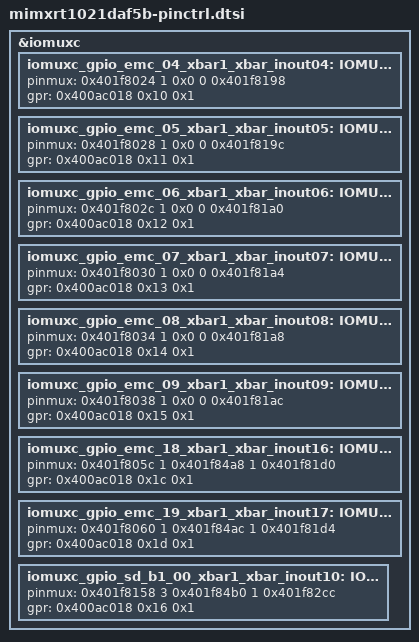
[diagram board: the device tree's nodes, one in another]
/*
 * Copyright 2024, NXP
 * SPDX-License-Identifier: Apache-2.0
 *
 * Note: File generated by gen_soc_headers.py
 * from configuration data for MIMXRT1021DAF5B
 */

/*
 * Delta-deduplicated by dedup_pinctrl.py:
 * based on mimxrt1024dag5a-pinctrl.dtsi with this part's differences applied
 * below (272 removed, 9 changed,
 * 0 added). Regenerate with dedup_pinctrl.py;
 * do not edit by hand.
 * target-hash: 459db1daa55398a1
 */

#include "mimxrt1024dag5a-pinctrl.dtsi"

/delete-node/ &iomuxc_gpio_ad_b0_13_arm_trace1;
/delete-node/ &iomuxc_gpio_ad_b0_14_arm_trace2;
/delete-node/ &iomuxc_gpio_ad_b0_15_arm_trace3;
/delete-node/ &iomuxc_gpio_ad_b1_06_acmp3_in3;
/delete-node/ &iomuxc_gpio_ad_b1_06_adc1_in6;
/delete-node/ &iomuxc_gpio_ad_b1_06_adc2_in6;
/delete-node/ &iomuxc_gpio_ad_b1_06_flexio1_flexio09;
/delete-node/ &iomuxc_gpio_ad_b1_06_flexpwm1_pwma0;
/delete-node/ &iomuxc_gpio_ad_b1_06_gpio1_io22;
/delete-node/ &iomuxc_gpio_ad_b1_06_kpp_col7;
/delete-node/ &iomuxc_gpio_ad_b1_06_lpspi1_pcs3;
/delete-node/ &iomuxc_gpio_ad_b1_06_lpuart2_cts_b;
/delete-node/ &iomuxc_gpio_ad_b1_06_sai1_rx_bclk;
/delete-node/ &iomuxc_gpio_ad_b1_06_usdhc1_reset_b;
/delete-node/ &iomuxc_gpio_ad_b1_07_acmp4_in3;
/delete-node/ &iomuxc_gpio_ad_b1_07_adc1_in7;
/delete-node/ &iomuxc_gpio_ad_b1_07_adc2_in7;
/delete-node/ &iomuxc_gpio_ad_b1_07_flexio1_flexio08;
/delete-node/ &iomuxc_gpio_ad_b1_07_flexpwm1_pwmb0;
/delete-node/ &iomuxc_gpio_ad_b1_07_gpio1_io23;
/delete-node/ &iomuxc_gpio_ad_b1_07_kpp_row7;
/delete-node/ &iomuxc_gpio_ad_b1_07_lpspi3_pcs3;
/delete-node/ &iomuxc_gpio_ad_b1_07_lpuart2_rts_b;
/delete-node/ &iomuxc_gpio_ad_b1_07_sai1_tx_data1;
/delete-node/ &iomuxc_gpio_ad_b1_07_usdhc1_vselect;
/delete-node/ &iomuxc_gpio_ad_b1_08_acmp1_in5;
/delete-node/ &iomuxc_gpio_ad_b1_08_adc1_in8;
/delete-node/ &iomuxc_gpio_ad_b1_08_adc2_in8;
/delete-node/ &iomuxc_gpio_ad_b1_08_flexio1_flexio07;
/delete-node/ &iomuxc_gpio_ad_b1_08_flexpwm1_pwma1;
/delete-node/ &iomuxc_gpio_ad_b1_08_gpio1_io24;
/delete-node/ &iomuxc_gpio_ad_b1_08_lpi2c2_scl;
/delete-node/ &iomuxc_gpio_ad_b1_08_lpspi3_pcs2;
/delete-node/ &iomuxc_gpio_ad_b1_08_lpuart2_tx;
/delete-node/ &iomuxc_gpio_ad_b1_08_sai1_tx_data2;
/delete-node/ &iomuxc_gpio_ad_b1_08_xbar1_xbar_in12;
/delete-node/ &iomuxc_gpio_ad_b1_08_xbar1_xbar_inout12;
/delete-node/ &iomuxc_gpio_ad_b1_09_acmp2_in5;
/delete-node/ &iomuxc_gpio_ad_b1_09_adc1_in9;
/delete-node/ &iomuxc_gpio_ad_b1_09_adc2_in9;
/delete-node/ &iomuxc_gpio_ad_b1_09_flexio1_flexio06;
/delete-node/ &iomuxc_gpio_ad_b1_09_flexpwm1_pwmb1;
/delete-node/ &iomuxc_gpio_ad_b1_09_gpio1_io25;
/delete-node/ &iomuxc_gpio_ad_b1_09_lpi2c2_sda;
/delete-node/ &iomuxc_gpio_ad_b1_09_lpspi3_pcs1;
/delete-node/ &iomuxc_gpio_ad_b1_09_lpuart2_rx;
/delete-node/ &iomuxc_gpio_ad_b1_09_sai1_tx_data3;
/delete-node/ &iomuxc_gpio_ad_b1_09_xbar1_xbar_in13;
/delete-node/ &iomuxc_gpio_ad_b1_09_xbar1_xbar_inout13;
/delete-node/ &iomuxc_gpio_emc_00_flexcan1_tx;
/delete-node/ &iomuxc_gpio_emc_00_gpio2_io00;
/delete-node/ &iomuxc_gpio_emc_00_lpspi2_sck;
/delete-node/ &iomuxc_gpio_emc_00_lpuart4_cts_b;
/delete-node/ &iomuxc_gpio_emc_00_pit_trigger2;
/delete-node/ &iomuxc_gpio_emc_00_qtimer2_timer0;
/delete-node/ &iomuxc_gpio_emc_00_semc_data00;
/delete-node/ &iomuxc_gpio_emc_00_spdif_sr_clk;
/delete-node/ &iomuxc_gpio_emc_01_flexcan1_rx;
/delete-node/ &iomuxc_gpio_emc_01_gpio2_io01;
/delete-node/ &iomuxc_gpio_emc_01_lpspi2_pcs0;
/delete-node/ &iomuxc_gpio_emc_01_lpuart4_rts_b;
/delete-node/ &iomuxc_gpio_emc_01_pit_trigger3;
/delete-node/ &iomuxc_gpio_emc_01_qtimer2_timer1;
/delete-node/ &iomuxc_gpio_emc_01_semc_data01;
/delete-node/ &iomuxc_gpio_emc_01_spdif_out;
/delete-node/ &iomuxc_gpio_emc_02_gpio2_io02;
/delete-node/ &iomuxc_gpio_emc_02_lpi2c1_scl;
/delete-node/ &iomuxc_gpio_emc_02_lpspi2_sdo;
/delete-node/ &iomuxc_gpio_emc_02_lpuart4_tx;
/delete-node/ &iomuxc_gpio_emc_02_qtimer2_timer2;
/delete-node/ &iomuxc_gpio_emc_02_semc_data02;
/delete-node/ &iomuxc_gpio_emc_02_spdif_lock;
/delete-node/ &iomuxc_gpio_emc_03_gpio2_io03;
/delete-node/ &iomuxc_gpio_emc_03_lpi2c1_sda;
/delete-node/ &iomuxc_gpio_emc_03_lpspi2_sdi;
/delete-node/ &iomuxc_gpio_emc_03_lpuart4_rx;
/delete-node/ &iomuxc_gpio_emc_03_qtimer2_timer3;
/delete-node/ &iomuxc_gpio_emc_03_semc_data03;
/delete-node/ &iomuxc_gpio_emc_03_spdif_ext_clk;
/delete-node/ &iomuxc_gpio_emc_10_flexpwm2_pwmx0;
/delete-node/ &iomuxc_gpio_emc_10_gpio2_io10;
/delete-node/ &iomuxc_gpio_emc_10_lpi2c4_sda;
/delete-node/ &iomuxc_gpio_emc_10_lpspi2_sck;
/delete-node/ &iomuxc_gpio_emc_10_sai1_tx_sync;
/delete-node/ &iomuxc_gpio_emc_10_semc_cas;
/delete-node/ &iomuxc_gpio_emc_10_xbar1_xbar_in10;
/delete-node/ &iomuxc_gpio_emc_10_xbar1_xbar_inout10;
/delete-node/ &iomuxc_gpio_emc_11_flexpwm2_pwmx1;
/delete-node/ &iomuxc_gpio_emc_11_gpio2_io11;
/delete-node/ &iomuxc_gpio_emc_11_lpi2c4_scl;
/delete-node/ &iomuxc_gpio_emc_11_lpspi2_pcs0;
/delete-node/ &iomuxc_gpio_emc_11_sai1_tx_bclk;
/delete-node/ &iomuxc_gpio_emc_11_semc_ras;
/delete-node/ &iomuxc_gpio_emc_11_xbar1_xbar_in11;
/delete-node/ &iomuxc_gpio_emc_11_xbar1_xbar_inout11;
/delete-node/ &iomuxc_gpio_emc_12_flexpwm2_pwmx2;
/delete-node/ &iomuxc_gpio_emc_12_gpio2_io12;
/delete-node/ &iomuxc_gpio_emc_12_lpspi2_sdo;
/delete-node/ &iomuxc_gpio_emc_12_lpuart6_tx;
/delete-node/ &iomuxc_gpio_emc_12_sai1_tx_data0;
/delete-node/ &iomuxc_gpio_emc_12_semc_cs0;
/delete-node/ &iomuxc_gpio_emc_12_xbar1_xbar_in12;
/delete-node/ &iomuxc_gpio_emc_12_xbar1_xbar_inout12;
/delete-node/ &iomuxc_gpio_emc_13_ccm_pmic_rdy;
/delete-node/ &iomuxc_gpio_emc_13_flexpwm2_pwmx3;
/delete-node/ &iomuxc_gpio_emc_13_gpio2_io13;
/delete-node/ &iomuxc_gpio_emc_13_lpspi2_sdi;
/delete-node/ &iomuxc_gpio_emc_13_lpuart6_rx;
/delete-node/ &iomuxc_gpio_emc_13_sai1_rx_data0;
/delete-node/ &iomuxc_gpio_emc_13_semc_ba0;
/delete-node/ &iomuxc_gpio_emc_13_xbar1_xbar_in13;
/delete-node/ &iomuxc_gpio_emc_13_xbar1_xbar_inout13;
/delete-node/ &iomuxc_gpio_emc_14_flexcan1_tx;
/delete-node/ &iomuxc_gpio_emc_14_gpio2_io14;
/delete-node/ &iomuxc_gpio_emc_14_lpspi2_pcs1;
/delete-node/ &iomuxc_gpio_emc_14_lpuart6_cts_b;
/delete-node/ &iomuxc_gpio_emc_14_sai1_rx_bclk;
/delete-node/ &iomuxc_gpio_emc_14_semc_ba1;
/delete-node/ &iomuxc_gpio_emc_14_xbar1_xbar_in14;
/delete-node/ &iomuxc_gpio_emc_14_xbar1_xbar_inout14;
/delete-node/ &iomuxc_gpio_emc_15_flexcan1_rx;
/delete-node/ &iomuxc_gpio_emc_15_gpio2_io15;
/delete-node/ &iomuxc_gpio_emc_15_lpuart6_rts_b;
/delete-node/ &iomuxc_gpio_emc_15_sai1_rx_sync;
/delete-node/ &iomuxc_gpio_emc_15_semc_addr10;
/delete-node/ &iomuxc_gpio_emc_15_wdog1_b;
/delete-node/ &iomuxc_gpio_emc_15_xbar1_xbar_in15;
/delete-node/ &iomuxc_gpio_emc_15_xbar1_xbar_inout15;
/delete-node/ &iomuxc_gpio_emc_28_ewm_out_b;
/delete-node/ &iomuxc_gpio_emc_28_flexpwm1_pwmx0;
/delete-node/ &iomuxc_gpio_emc_28_flexpwm2_pwma3;
/delete-node/ &iomuxc_gpio_emc_28_gpio2_io28;
/delete-node/ &iomuxc_gpio_emc_28_gpt2_capture2;
/delete-node/ &iomuxc_gpio_emc_28_sai3_mclk;
/delete-node/ &iomuxc_gpio_emc_28_semc_dqs;
/delete-node/ &iomuxc_gpio_emc_28_xbar1_xbar_in18;
/delete-node/ &iomuxc_gpio_emc_28_xbar1_xbar_inout18;
/delete-node/ &iomuxc_gpio_emc_29_flexpwm1_pwmx1;
/delete-node/ &iomuxc_gpio_emc_29_flexpwm2_pwmb3;
/delete-node/ &iomuxc_gpio_emc_29_gpio2_io29;
/delete-node/ &iomuxc_gpio_emc_29_gpt2_compare2;
/delete-node/ &iomuxc_gpio_emc_29_sai3_rx_bclk;
/delete-node/ &iomuxc_gpio_emc_29_semc_cke;
/delete-node/ &iomuxc_gpio_emc_29_wdog2_rst_b_deb;
/delete-node/ &iomuxc_gpio_emc_29_xbar1_xbar_in19;
/delete-node/ &iomuxc_gpio_emc_29_xbar1_xbar_inout19;
/delete-node/ &iomuxc_gpio_emc_30_flexpwm1_pwmx2;
/delete-node/ &iomuxc_gpio_emc_30_flexpwm2_pwma2;
/delete-node/ &iomuxc_gpio_emc_30_gpio2_io30;
/delete-node/ &iomuxc_gpio_emc_30_gpt2_compare3;
/delete-node/ &iomuxc_gpio_emc_30_lpuart4_cts_b;
/delete-node/ &iomuxc_gpio_emc_30_sai3_rx_sync;
/delete-node/ &iomuxc_gpio_emc_30_semc_clk;
/delete-node/ &iomuxc_gpio_emc_30_wdog1_rst_b_deb;
/delete-node/ &iomuxc_gpio_emc_31_flexpwm1_pwmx3;
/delete-node/ &iomuxc_gpio_emc_31_flexpwm2_pwmb2;
/delete-node/ &iomuxc_gpio_emc_31_gpio2_io31;
/delete-node/ &iomuxc_gpio_emc_31_gpt2_clk;
/delete-node/ &iomuxc_gpio_emc_31_lpuart4_rts_b;
/delete-node/ &iomuxc_gpio_emc_31_sai3_rx_data;
/delete-node/ &iomuxc_gpio_emc_31_semc_dm1;
/delete-node/ &iomuxc_gpio_emc_31_wdog2_b;
/delete-node/ &iomuxc_gpio_emc_36_ccm_pmic_rdy;
/delete-node/ &iomuxc_gpio_emc_36_enet_rx_clk;
/delete-node/ &iomuxc_gpio_emc_36_flexpwm2_pwma1;
/delete-node/ &iomuxc_gpio_emc_36_gpio3_io04;
/delete-node/ &iomuxc_gpio_emc_36_lpspi4_pcs1;
/delete-node/ &iomuxc_gpio_emc_36_lpuart5_cts_b;
/delete-node/ &iomuxc_gpio_emc_36_semc_data12;
/delete-node/ &iomuxc_gpio_emc_36_usdhc1_wp;
/delete-node/ &iomuxc_gpio_emc_37_enet_rx_data3;
/delete-node/ &iomuxc_gpio_emc_37_flexpwm2_pwmb1;
/delete-node/ &iomuxc_gpio_emc_37_gpio3_io05;
/delete-node/ &iomuxc_gpio_emc_37_lpspi4_pcs2;
/delete-node/ &iomuxc_gpio_emc_37_lpuart5_rts_b;
/delete-node/ &iomuxc_gpio_emc_37_mqs_right;
/delete-node/ &iomuxc_gpio_emc_37_semc_data13;
/delete-node/ &iomuxc_gpio_emc_37_usdhc1_vselect;
/delete-node/ &iomuxc_gpio_emc_38_enet_rx_data2;
/delete-node/ &iomuxc_gpio_emc_38_flexpwm2_pwma0;
/delete-node/ &iomuxc_gpio_emc_38_gpio3_io06;
/delete-node/ &iomuxc_gpio_emc_38_lpspi4_pcs3;
/delete-node/ &iomuxc_gpio_emc_38_lpuart5_tx;
/delete-node/ &iomuxc_gpio_emc_38_mqs_left;
/delete-node/ &iomuxc_gpio_emc_38_semc_data14;
/delete-node/ &iomuxc_gpio_emc_38_usdhc1_cd_b;
/delete-node/ &iomuxc_gpio_emc_39_enet_tx_er;
/delete-node/ &iomuxc_gpio_emc_39_flexpwm2_pwmb0;
/delete-node/ &iomuxc_gpio_emc_39_gpio3_io07;
/delete-node/ &iomuxc_gpio_emc_39_gpt1_clk;
/delete-node/ &iomuxc_gpio_emc_39_lpuart5_rx;
/delete-node/ &iomuxc_gpio_emc_39_semc_data15;
/delete-node/ &iomuxc_gpio_emc_39_usb_otg1_oc;
/delete-node/ &iomuxc_gpio_emc_39_wdog1_b;
/delete-node/ &iomuxc_gpio_emc_40_enet_mdio;
/delete-node/ &iomuxc_gpio_emc_40_enet_tx_data3;
/delete-node/ &iomuxc_gpio_emc_40_gpio3_io08;
/delete-node/ &iomuxc_gpio_emc_40_gpt1_compare3;
/delete-node/ &iomuxc_gpio_emc_40_semc_csx0;
/delete-node/ &iomuxc_gpio_emc_40_spdif_out;
/delete-node/ &iomuxc_gpio_emc_40_usb_otg1_id;
/delete-node/ &iomuxc_gpio_emc_40_xbar1_xbar_in18;
/delete-node/ &iomuxc_gpio_emc_40_xbar1_xbar_inout18;
/delete-node/ &iomuxc_gpio_emc_41_enet_mdc;
/delete-node/ &iomuxc_gpio_emc_41_enet_tx_data2;
/delete-node/ &iomuxc_gpio_emc_41_gpio3_io09;
/delete-node/ &iomuxc_gpio_emc_41_gpt1_compare2;
/delete-node/ &iomuxc_gpio_emc_41_semc_rdy;
/delete-node/ &iomuxc_gpio_emc_41_spdif_in;
/delete-node/ &iomuxc_gpio_emc_41_usb_otg1_pwr;
/delete-node/ &iomuxc_gpio_emc_41_xbar1_xbar_in19;
/delete-node/ &iomuxc_gpio_emc_41_xbar1_xbar_inout19;
/delete-node/ &iomuxc_gpio_sd_b0_00_flexspi_a_ss1_b;
/delete-node/ &iomuxc_gpio_sd_b0_00_gpio3_io13;
/delete-node/ &iomuxc_gpio_sd_b0_00_lpi2c3_scl;
/delete-node/ &iomuxc_gpio_sd_b0_00_qtimer1_timer0;
/delete-node/ &iomuxc_gpio_sd_b0_00_sai1_mclk;
/delete-node/ &iomuxc_gpio_sd_b0_00_sai2_mclk;
/delete-node/ &iomuxc_gpio_sd_b0_00_usdhc1_data2;
/delete-node/ &iomuxc_gpio_sd_b0_00_xbar1_xbar_in14;
/delete-node/ &iomuxc_gpio_sd_b0_00_xbar1_xbar_inout14;
/delete-node/ &iomuxc_gpio_sd_b0_01_flexspi_b_ss1_b;
/delete-node/ &iomuxc_gpio_sd_b0_01_gpio3_io14;
/delete-node/ &iomuxc_gpio_sd_b0_01_lpi2c3_sda;
/delete-node/ &iomuxc_gpio_sd_b0_01_qtimer1_timer1;
/delete-node/ &iomuxc_gpio_sd_b0_01_ref_24m_out;
/delete-node/ &iomuxc_gpio_sd_b0_01_sai2_rx_sync;
/delete-node/ &iomuxc_gpio_sd_b0_01_usdhc1_data3;
/delete-node/ &iomuxc_gpio_sd_b0_01_xbar1_xbar_in15;
/delete-node/ &iomuxc_gpio_sd_b0_01_xbar1_xbar_inout15;
/delete-node/ &iomuxc_gpio_sd_b0_02_enet_mdio;
/delete-node/ &iomuxc_gpio_sd_b0_02_gpio3_io15;
/delete-node/ &iomuxc_gpio_sd_b0_02_lpspi1_sck;
/delete-node/ &iomuxc_gpio_sd_b0_02_lpuart7_cts_b;
/delete-node/ &iomuxc_gpio_sd_b0_02_qtimer1_timer2;
/delete-node/ &iomuxc_gpio_sd_b0_02_sai2_rx_bclk;
/delete-node/ &iomuxc_gpio_sd_b0_02_usdhc1_cmd;
/delete-node/ &iomuxc_gpio_sd_b0_02_xbar1_xbar_in16;
/delete-node/ &iomuxc_gpio_sd_b0_02_xbar1_xbar_inout16;
/delete-node/ &iomuxc_gpio_sd_b0_03_enet_mdc;
/delete-node/ &iomuxc_gpio_sd_b0_03_gpio3_io16;
/delete-node/ &iomuxc_gpio_sd_b0_03_lpspi1_pcs0;
/delete-node/ &iomuxc_gpio_sd_b0_03_lpuart7_rts_b;
/delete-node/ &iomuxc_gpio_sd_b0_03_qtimer1_timer3;
/delete-node/ &iomuxc_gpio_sd_b0_03_sai2_rx_data;
/delete-node/ &iomuxc_gpio_sd_b0_03_usdhc1_clk;
/delete-node/ &iomuxc_gpio_sd_b0_04_flexcan2_tx;
/delete-node/ &iomuxc_gpio_sd_b0_04_flexspi_b_ss0_b;
/delete-node/ &iomuxc_gpio_sd_b0_04_gpio3_io17;
/delete-node/ &iomuxc_gpio_sd_b0_04_lpspi1_sdo;
/delete-node/ &iomuxc_gpio_sd_b0_04_lpuart7_tx;
/delete-node/ &iomuxc_gpio_sd_b0_04_sai2_tx_data;
/delete-node/ &iomuxc_gpio_sd_b0_04_usdhc1_data0;
/delete-node/ &iomuxc_gpio_sd_b0_05_flexcan2_rx;
/delete-node/ &iomuxc_gpio_sd_b0_05_flexspi_b_dqs;
/delete-node/ &iomuxc_gpio_sd_b0_05_gpio3_io18;
/delete-node/ &iomuxc_gpio_sd_b0_05_lpspi1_sdi;
/delete-node/ &iomuxc_gpio_sd_b0_05_lpuart7_rx;
/delete-node/ &iomuxc_gpio_sd_b0_05_sai2_tx_bclk;
/delete-node/ &iomuxc_gpio_sd_b0_05_usdhc1_data1;
/delete-node/ &iomuxc_gpio_sd_b0_06_gpio3_io19;
/delete-node/ &iomuxc_gpio_sd_b0_06_ref_32k_out;
/delete-node/ &iomuxc_gpio_sd_b0_06_sai2_tx_sync;
/delete-node/ &iomuxc_gpio_sd_b0_06_usdhc1_cd_b;
/delete-node/ &iomuxc_gpio_sd_b0_06_usdhc1_reset_b;
/delete-node/ &iomuxc_gpio_sd_b0_06_wdog1_b;
/delete-node/ &iomuxc_gpio_sd_b0_06_xbar1_xbar_in17;
/delete-node/ &iomuxc_gpio_sd_b0_06_xbar1_xbar_inout17;
/delete-node/ &iomuxc_snvs_pmic_stby_req_ccm_pmic_vstby_req;
/delete-node/ &iomuxc_snvs_pmic_stby_req_gpio5_io02;
/delete-node/ &iomuxc_snvs_wakeup_arm_nmi;
/delete-node/ &iomuxc_snvs_wakeup_gpio5_io00;
/delete-node/ &iomuxc_gpio_emc_04_xbar1_xbar_inout04;
/delete-node/ &iomuxc_gpio_emc_05_xbar1_xbar_inout05;
/delete-node/ &iomuxc_gpio_emc_06_xbar1_xbar_inout06;
/delete-node/ &iomuxc_gpio_emc_07_xbar1_xbar_inout07;
/delete-node/ &iomuxc_gpio_emc_08_xbar1_xbar_inout08;
/delete-node/ &iomuxc_gpio_emc_09_xbar1_xbar_inout09;
/delete-node/ &iomuxc_gpio_emc_18_xbar1_xbar_inout16;
/delete-node/ &iomuxc_gpio_emc_19_xbar1_xbar_inout17;
/delete-node/ &iomuxc_gpio_sd_b1_00_xbar1_xbar_inout10;

&iomuxc {
	/omit-if-no-ref/ iomuxc_gpio_emc_04_xbar1_xbar_inout04: IOMUXC_GPIO_EMC_04_XBAR1_XBAR_INOUT04 {
		pinmux = <0x401f8024 1 0x0 0 0x401f8198>;
		gpr = <0x400ac018 0x10 0x1>;
	};
	/omit-if-no-ref/ iomuxc_gpio_emc_05_xbar1_xbar_inout05: IOMUXC_GPIO_EMC_05_XBAR1_XBAR_INOUT05 {
		pinmux = <0x401f8028 1 0x0 0 0x401f819c>;
		gpr = <0x400ac018 0x11 0x1>;
	};
	/omit-if-no-ref/ iomuxc_gpio_emc_06_xbar1_xbar_inout06: IOMUXC_GPIO_EMC_06_XBAR1_XBAR_INOUT06 {
		pinmux = <0x401f802c 1 0x0 0 0x401f81a0>;
		gpr = <0x400ac018 0x12 0x1>;
	};
	/omit-if-no-ref/ iomuxc_gpio_emc_07_xbar1_xbar_inout07: IOMUXC_GPIO_EMC_07_XBAR1_XBAR_INOUT07 {
		pinmux = <0x401f8030 1 0x0 0 0x401f81a4>;
		gpr = <0x400ac018 0x13 0x1>;
	};
	/omit-if-no-ref/ iomuxc_gpio_emc_08_xbar1_xbar_inout08: IOMUXC_GPIO_EMC_08_XBAR1_XBAR_INOUT08 {
		pinmux = <0x401f8034 1 0x0 0 0x401f81a8>;
		gpr = <0x400ac018 0x14 0x1>;
	};
	/omit-if-no-ref/ iomuxc_gpio_emc_09_xbar1_xbar_inout09: IOMUXC_GPIO_EMC_09_XBAR1_XBAR_INOUT09 {
		pinmux = <0x401f8038 1 0x0 0 0x401f81ac>;
		gpr = <0x400ac018 0x15 0x1>;
	};
	/omit-if-no-ref/ iomuxc_gpio_emc_18_xbar1_xbar_inout16: IOMUXC_GPIO_EMC_18_XBAR1_XBAR_INOUT16 {
		pinmux = <0x401f805c 1 0x401f84a8 1 0x401f81d0>;
		gpr = <0x400ac018 0x1c 0x1>;
	};
	/omit-if-no-ref/ iomuxc_gpio_emc_19_xbar1_xbar_inout17: IOMUXC_GPIO_EMC_19_XBAR1_XBAR_INOUT17 {
		pinmux = <0x401f8060 1 0x401f84ac 1 0x401f81d4>;
		gpr = <0x400ac018 0x1d 0x1>;
	};
	/omit-if-no-ref/ iomuxc_gpio_sd_b1_00_xbar1_xbar_inout10: IOMUXC_GPIO_SD_B1_00_XBAR1_XBAR_INOUT10 {
		pinmux = <0x401f8158 3 0x401f84b0 1 0x401f82cc>;
		gpr = <0x400ac018 0x16 0x1>;
	};
};
